# RA2A1 register map
Vendor: Renesas Electronics Corporation; Series: RA2; File version: 1.1
CPU: other r1p0, little endian, MPU, no FPU, VTOR, 2 interrupt priority bits
Registers are 8-bit, read-write, reset 0x0 unless marked. A register's access mark holds for its fields unless they carry their own. Offsets are from the block's base; [hi:lo] are bit positions; {n}, {i} and the like mark numbered series; 'fields as' and 'values as' point back to an identical list.

## PFS — Pmn Pin Function Control Register
Base 0x40040800
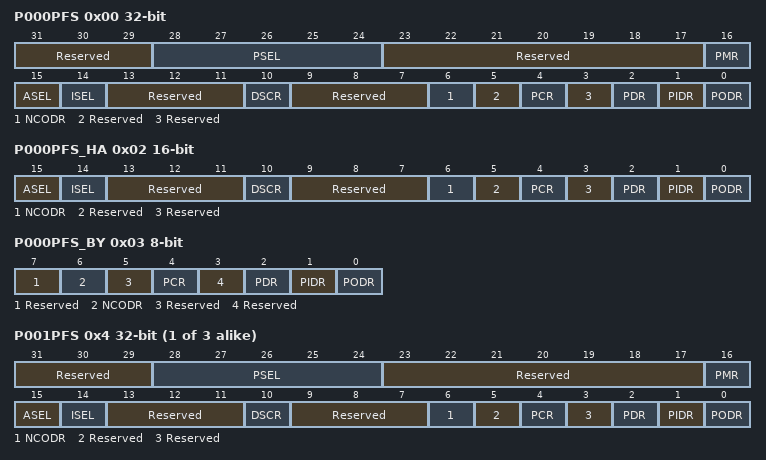
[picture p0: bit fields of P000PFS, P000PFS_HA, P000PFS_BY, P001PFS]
0x00 P000PFS 32-bit — P000 Pin Function Control Register
  [31:29] Reserved — These bits are read as 000. The write value should be 000.
  [28:24] PSEL — Port Function Select These bits select the peripheral function. For individual pin functions, see the MPC table
  [23:17] Reserved — These bits are read as 0000000. The write value should be 0000000.
  [16] PMR — Port Mode Control
    0=Uses the pin as a general I/O pin; 1=Uses the pin as an I/O port for peripheral functions
  [15] ASEL — Analog Input enable
    0=Used other than as analog pin; 1=Used as analog pin
  [14] ISEL — IRQ input enable
    0=Not used as IRQn input pin; 1=Used as IRQn input pin
  [13:11] Reserved — These bits are read as 000. The write value should be 000.
  [10] DSCR — Drive Strength Control Register
    0=Low drive; 1=High drive
  [9:7] Reserved — These bits are read as 000. The write value should be 000.
  [6] NCODR — N-Channel Open Drain Control
    0=CMOS output; 1=NMOS open-drain output
  [5] Reserved — This bit is read as 0. The write value should be 0.
  [4] PCR — Pull-up Control
    0=Disables an input pull-up; 1=Enables an input pull-up
  [3] Reserved — This bit is read as 0. The write value should be 0.
  [2] PDR — Port Direction
    0=Input (Functions as an input pin.); 1=Output (Functions as an output pin.)
  [1] PIDR ro — Port Input Data
    0=Low input; 1=High input
  [0] PODR — Port Output Data
    0=Low output; 1=High output
0x02 P000PFS_HA 16-bit — P000 Pin Function Control Register
  [15] ASEL — Analog Input enable
    0=Used other than as analog pin; 1=Used as analog pin
  [14] ISEL — IRQ input enable
    0=Not used as IRQn input pin; 1=Used as IRQn input pin
  [13:11] Reserved — These bits are read as 000. The write value should be 000.
  [10] DSCR — Drive Strength Control Register
    0=Low drive; 1=High drive
  [9:7] Reserved — These bits are read as 000. The write value should be 000.
  [6] NCODR — N-Channel Open Drain Control
    0=CMOS output; 1=NMOS open-drain output
  [5] Reserved — This bit is read as 0. The write value should be 0.
  [4] PCR — Pull-up Control
    0=Disables an input pull-up; 1=Enables an input pull-up
  [3] Reserved — This bit is read as 0. The write value should be 0.
  [2] PDR — Port Direction
    values as P000PFS.PDR
  [1] PIDR ro — Port Input Data
    0=Low input; 1=High input
  [0] PODR — Port Output Data
    0=Low output; 1=High output
0x03 P000PFS_BY — P000 Pin Function Control Register
  [7] Reserved — This bit is read as 0. The write value should be 0.
  [6] NCODR — N-Channel Open Drain Control
    0=CMOS output; 1=NMOS open-drain output
  [5] Reserved — This bit is read as 0. The write value should be 0.
  [4] PCR — Pull-up Control
    0=Disables an input pull-up; 1=Enables an input pull-up
  [3] Reserved — This bit is read as 0. The write value should be 0.
  [2] PDR — Port Direction
    values as P000PFS.PDR
  [1] PIDR ro — Port Input Data
    0=Low input; 1=High input
  [0] PODR — Port Output Data
    0=Low output; 1=High output
{0x0+4i} P00{i}PFS (i=1..3) 32-bit — P00{i} Pin Function Control Register
  fields as P000PFS
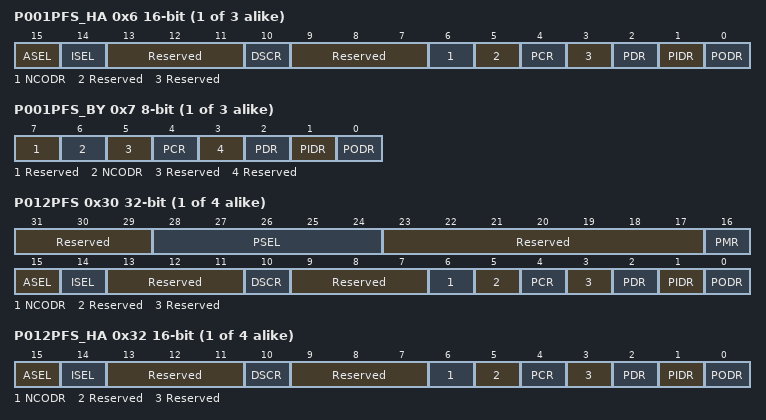
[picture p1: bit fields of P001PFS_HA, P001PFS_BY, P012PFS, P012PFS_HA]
{0x2+4i} P00{i}PFS_HA (i=1..3) 16-bit — P00{i} Pin Function Control Register
  fields as P000PFS_HA
{0x3+4i} P00{i}PFS_BY (i=1..3) — P00{i} Pin Function Control Register
  fields as P000PFS_BY
{0x0+4i} P0{i}PFS (i=12..15) 32-bit — P0{i} Pin Function Control Register
  fields as P000PFS
{0x2+4i} P0{i}PFS_HA (i=12..15) 16-bit — P0{i} Pin Function Control Register
  fields as P000PFS_HA
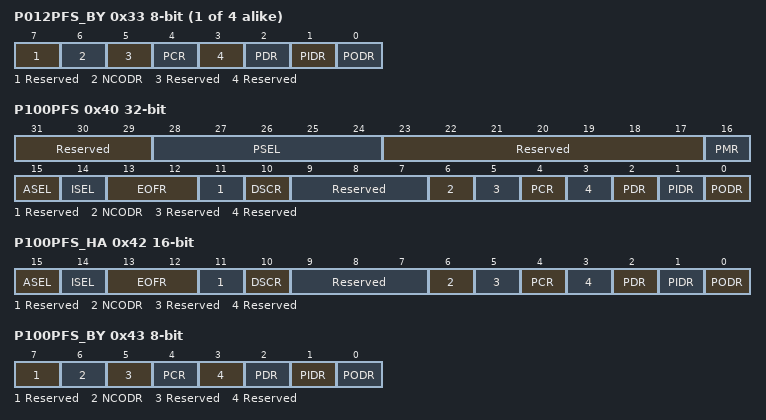
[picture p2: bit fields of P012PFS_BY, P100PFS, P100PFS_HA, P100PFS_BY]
{0x3+4i} P0{i}PFS_BY (i=12..15) — P0{i} Pin Function Control Register
  fields as P000PFS_BY
0x40 P100PFS 32-bit — P100 Pin Function Control Register
  [31:29] Reserved — These bits are read as 000. The write value should be 000.
  [28:24] PSEL — Port Function Select These bits select the peripheral function. For individual pin functions, see the MPC table
  [23:17] Reserved — These bits are read as 0000000. The write value should be 0000000.
  [16] PMR — Port Mode Control
    values as P000PFS.PMR
  [15] ASEL — Analog Input enable
    0=Used other than as analog pin; 1=Used as analog pin
  [14] ISEL — IRQ input enable
    0=Not used as IRQn input pin; 1=Used as IRQn input pin
  [13:12] EOFR — Event on Falling/Event on Rising
    0=Don't care; 1=Detect rising edge; 2=Detect falling edge; 3=Detect both edge
  [11] Reserved — This bit is read as 0. The write value should be 0.
  [10] DSCR — Drive Strength Control Register
    0=Low drive; 1=High drive
  [9:7] Reserved — These bits are read as 000. The write value should be 000.
  [6] NCODR — N-Channel Open Drain Control
    0=CMOS output; 1=NMOS open-drain output
  [5] Reserved — This bit is read as 0. The write value should be 0.
  [4] PCR — Pull-up Control
    0=Disables an input pull-up; 1=Enables an input pull-up
  [3] Reserved — This bit is read as 0. The write value should be 0.
  [2] PDR — Port Direction
    values as P000PFS.PDR
  [1] PIDR ro — Port Input Data
    0=Low input; 1=High input
  [0] PODR — Port Output Data
    0=Low output; 1=High output
0x42 P100PFS_HA 16-bit — P100 Pin Function Control Register
  [15] ASEL — Analog Input enable
    0=Used other than as analog pin; 1=Used as analog pin
  [14] ISEL — IRQ input enable
    0=Not used as IRQn input pin; 1=Used as IRQn input pin
  [13:12] EOFR — Event on Falling/Event on Rising
    values as P100PFS.EOFR
  [11] Reserved — This bit is read as 0. The write value should be 0.
  [10] DSCR — Drive Strength Control Register
    0=Low drive; 1=High drive
  [9:7] Reserved — These bits are read as 000. The write value should be 000.
  [6] NCODR — N-Channel Open Drain Control
    0=CMOS output; 1=NMOS open-drain output
  [5] Reserved — This bit is read as 0. The write value should be 0.
  [4] PCR — Pull-up Control
    0=Disables an input pull-up; 1=Enables an input pull-up
  [3] Reserved — This bit is read as 0. The write value should be 0.
  [2] PDR — Port Direction
    values as P000PFS.PDR
  [1] PIDR ro — Port Input Data
    0=Low input; 1=High input
  [0] PODR — Port Output Data
    0=Low output; 1=High output
0x43 P100PFS_BY — P100 Pin Function Control Register
  fields as P000PFS_BY
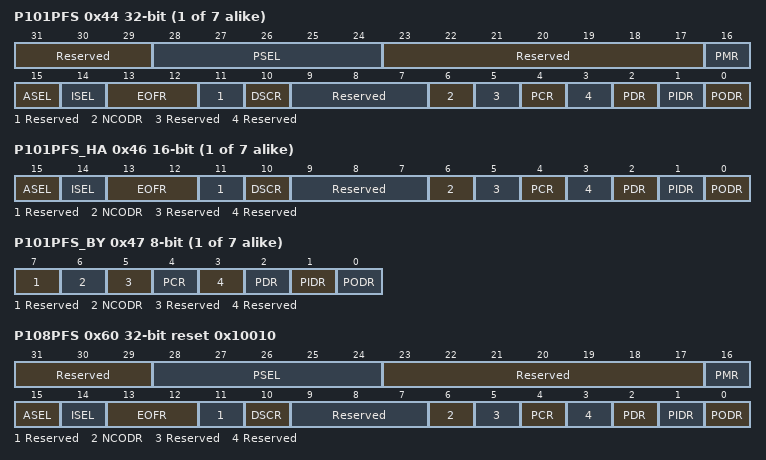
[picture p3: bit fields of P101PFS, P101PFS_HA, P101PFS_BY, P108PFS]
{0x40+4i} P10{i}PFS (i=1..7) 32-bit — P10{i} Pin Function Control Register
  fields as P100PFS
{0x42+4i} P10{i}PFS_HA (i=1..7) 16-bit — P10{i} Pin Function Control Register
  fields as P100PFS_HA
{0x43+4i} P10{i}PFS_BY (i=1..7) — P10{i} Pin Function Control Register
  fields as P000PFS_BY
0x60 P108PFS 32-bit reset 0x10010 — P108 Pin Function Control Register
  fields as P100PFS
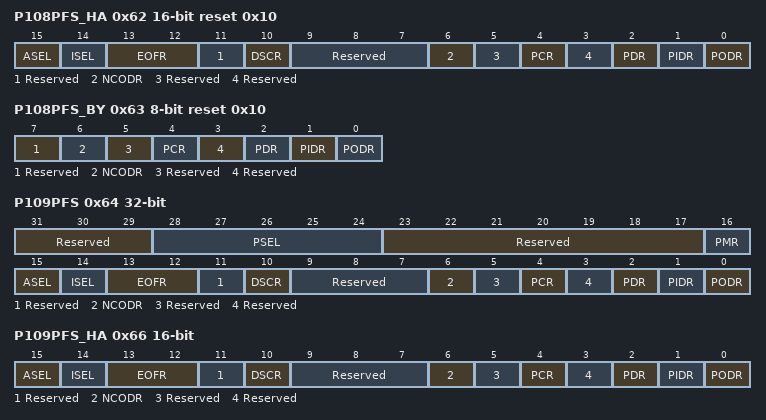
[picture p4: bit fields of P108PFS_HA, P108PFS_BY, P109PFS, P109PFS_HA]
0x62 P108PFS_HA 16-bit reset 0x10 — P108 Pin Function Control Register
  fields as P100PFS_HA
0x63 P108PFS_BY reset 0x10 — P108 Pin Function Control Register
  fields as P000PFS_BY
0x64 P109PFS 32-bit — P109 Pin Function Control Register
  fields as P100PFS
0x66 P109PFS_HA 16-bit — P109 Pin Function Control Register
  fields as P100PFS_HA
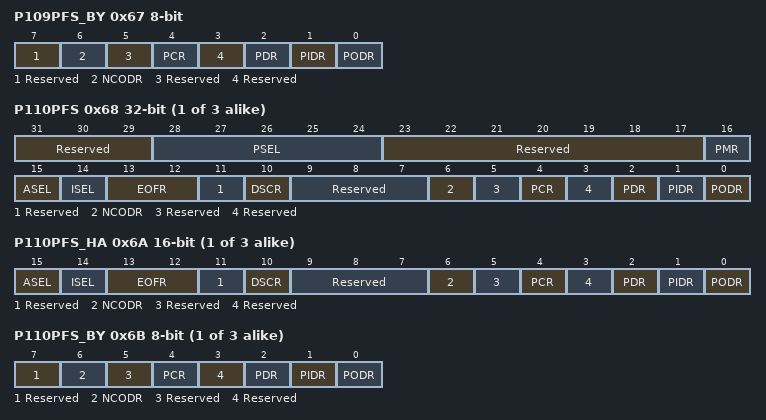
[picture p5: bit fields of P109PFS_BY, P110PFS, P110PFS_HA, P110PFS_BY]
0x67 P109PFS_BY — P109 Pin Function Control Register
  fields as P000PFS_BY
{0x40+4i} P1{i}PFS (i=10..12) 32-bit — P1{i} Pin Function Control Register
  fields as P100PFS
{0x42+4i} P1{i}PFS_HA (i=10..12) 16-bit — P1{i} Pin Function Control Register
  fields as P100PFS_HA
{0x43+4i} P1{i}PFS_BY (i=10..12) — P1{i} Pin Function Control Register
  fields as P000PFS_BY
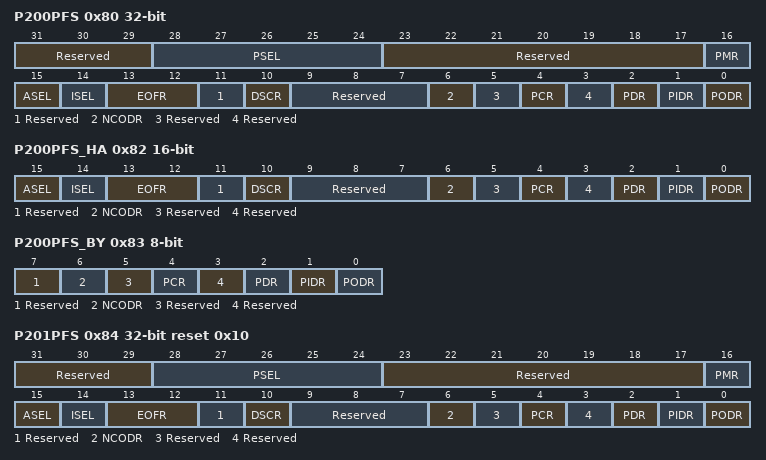
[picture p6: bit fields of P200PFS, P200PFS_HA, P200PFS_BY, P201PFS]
0x80 P200PFS 32-bit — P200 Pin Function Control Register
  fields as P100PFS
0x82 P200PFS_HA 16-bit — P200 Pin Function Control Register
  fields as P100PFS_HA
0x83 P200PFS_BY — P200 Pin Function Control Register
  fields as P000PFS_BY
0x84 P201PFS 32-bit reset 0x10 — P201 Pin Function Control Register
  fields as P100PFS
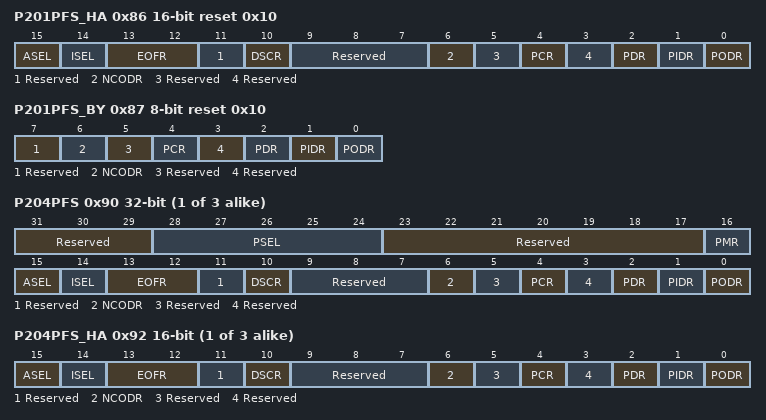
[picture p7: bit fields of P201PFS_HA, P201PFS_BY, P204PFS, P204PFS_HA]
0x86 P201PFS_HA 16-bit reset 0x10 — P201 Pin Function Control Register
  fields as P100PFS_HA
0x87 P201PFS_BY reset 0x10 — P201 Pin Function Control Register
  fields as P000PFS_BY
{0x80+4i} P20{i}PFS (i=4..6) 32-bit — P20{i} Pin Function Control Register
  fields as P100PFS
{0x82+4i} P20{i}PFS_HA (i=4..6) 16-bit — P20{i} Pin Function Control Register
  fields as P100PFS_HA
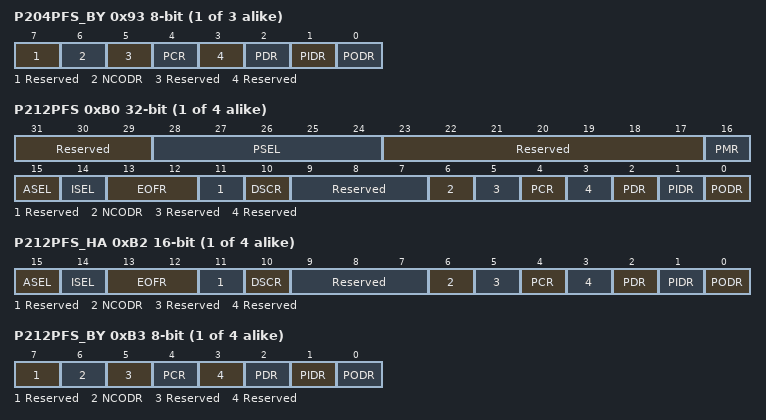
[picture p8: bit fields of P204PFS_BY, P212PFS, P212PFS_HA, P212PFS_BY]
{0x83+4i} P20{i}PFS_BY (i=4..6) — P20{i} Pin Function Control Register
  fields as P000PFS_BY
{0x80+4i} P2{i}PFS (i=12..15) 32-bit — P2{i} Pin Function Control Register
  fields as P100PFS
{0x82+4i} P2{i}PFS_HA (i=12..15) 16-bit — P2{i} Pin Function Control Register
  fields as P100PFS_HA
{0x83+4i} P2{i}PFS_BY (i=12..15) — P2{i} Pin Function Control Register
  fields as P000PFS_BY
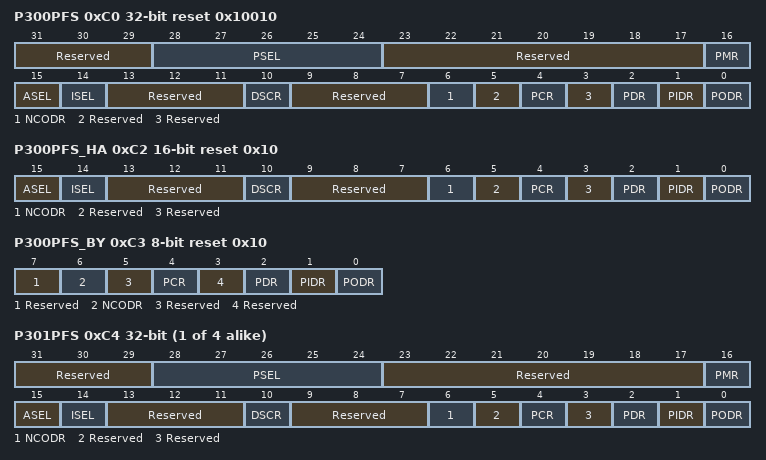
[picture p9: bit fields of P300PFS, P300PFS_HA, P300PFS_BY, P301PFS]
0xC0 P300PFS 32-bit reset 0x10010 — P300 Pin Function Control Register
  fields as P000PFS
0xC2 P300PFS_HA 16-bit reset 0x10 — P300 Pin Function Control Register
  fields as P000PFS_HA
0xC3 P300PFS_BY reset 0x10 — P300 Pin Function Control Register
  fields as P000PFS_BY
{0xC0+4i} P30{i}PFS (i=1..4) 32-bit — P30{i} Pin Function Control Register
  fields as P000PFS
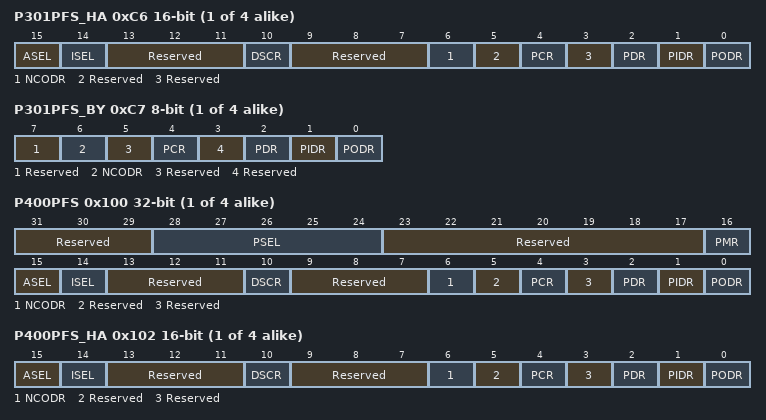
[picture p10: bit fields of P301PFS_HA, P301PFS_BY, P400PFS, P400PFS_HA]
{0xC2+4i} P30{i}PFS_HA (i=1..4) 16-bit — P30{i} Pin Function Control Register
  fields as P000PFS_HA
{0xC3+4i} P30{i}PFS_BY (i=1..4) — P30{i} Pin Function Control Register
  fields as P000PFS_BY
{0x100+4i} P40{i}PFS (i=0..3) 32-bit — P40{i} Pin Function Control Register
  fields as P000PFS
{0x102+4i} P40{i}PFS_HA (i=0..3) 16-bit — P40{i} Pin Function Control Register
  fields as P000PFS_HA
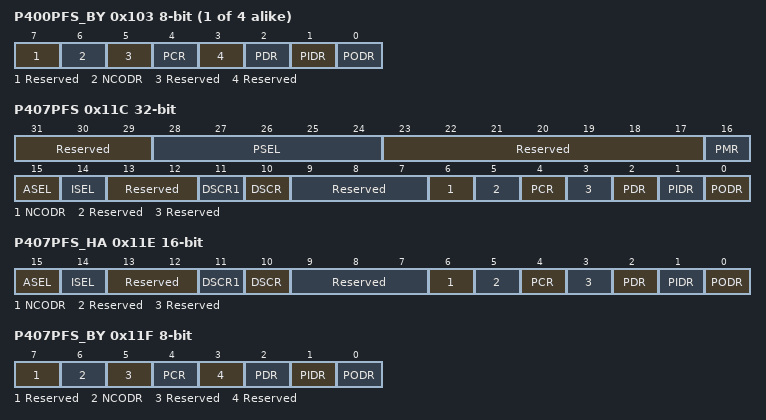
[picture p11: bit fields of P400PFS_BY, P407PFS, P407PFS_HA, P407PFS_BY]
{0x103+4i} P40{i}PFS_BY (i=0..3) — P40{i} Pin Function Control Register
  fields as P000PFS_BY
0x11C P407PFS 32-bit — P407 Pin Function Control Register
  [31:29] Reserved — These bits are read as 000. The write value should be 000.
  [28:24] PSEL — Port Function Select These bits select the peripheral function. For individual pin functions, see the MPC table
  [23:17] Reserved — These bits are read as 0000000. The write value should be 0000000.
  [16] PMR — Port Mode Control
    values as P000PFS.PMR
  [15] ASEL — Analog Input enable
    0=Used other than as analog pin; 1=Used as analog pin
  [14] ISEL — IRQ input enable
    0=Not used as IRQn input pin; 1=Used as IRQn input pin
  [13:12] Reserved — These bits are read as 00. The write value should be 00.
  [11] DSCR1 — Drive Strength Control Register
    0=Low drive; 1=Middle drive; 2=Middle drive for IIC Fast-mode and SPI; 3=Setting prohibited
  [10] DSCR
  [9:7] Reserved — These bits are read as 000. The write value should be 000.
  [6] NCODR — N-Channel Open Drain Control
    0=CMOS output; 1=NMOS open-drain output
  [5] Reserved — This bit is read as 0. The write value should be 0.
  [4] PCR — Pull-up Control
    0=Disables an input pull-up; 1=Enables an input pull-up
  [3] Reserved — This bit is read as 0. The write value should be 0.
  [2] PDR — Port Direction
    values as P000PFS.PDR
  [1] PIDR ro — Port Input Data
    0=Low input; 1=High input
  [0] PODR — Port Output Data
    0=Low output; 1=High output
0x11E P407PFS_HA 16-bit — P407 Pin Function Control Register
  [15] ASEL — Analog Input enable
    0=Used other than as analog pin; 1=Used as analog pin
  [14] ISEL — IRQ input enable
    0=Not used as IRQn input pin; 1=Used as IRQn input pin
  [13:12] Reserved — These bits are read as 00. The write value should be 00.
  [11] DSCR1 — Drive Strength Control Register
    values as P407PFS.DSCR1
  [10] DSCR
  [9:7] Reserved — These bits are read as 000. The write value should be 000.
  [6] NCODR — N-Channel Open Drain Control
    0=CMOS output; 1=NMOS open-drain output
  [5] Reserved — This bit is read as 0. The write value should be 0.
  [4] PCR — Pull-up Control
    0=Disables an input pull-up; 1=Enables an input pull-up
  [3] Reserved — This bit is read as 0. The write value should be 0.
  [2] PDR — Port Direction
    values as P000PFS.PDR
  [1] PIDR ro — Port Input Data
    0=Low input; 1=High input
  [0] PODR — Port Output Data
    0=Low output; 1=High output
0x11F P407PFS_BY — P407 Pin Function Control Register
  fields as P000PFS_BY
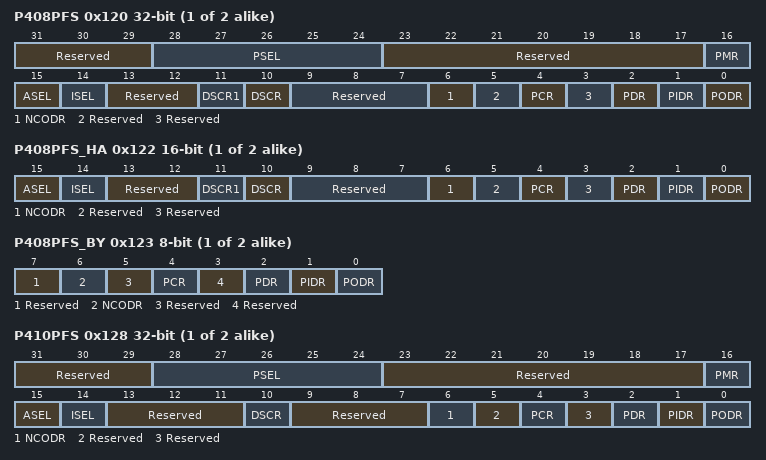
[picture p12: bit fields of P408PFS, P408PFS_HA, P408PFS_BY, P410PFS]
{0x100+4i} P40{i}PFS (i=8..9) 32-bit — P40{i} Pin Function Control Register
  fields as P407PFS
{0x102+4i} P40{i}PFS_HA (i=8..9) 16-bit — P40{i} Pin Function Control Register
  fields as P407PFS_HA
{0x103+4i} P40{i}PFS_BY (i=8..9) — P40{i} Pin Function Control Register
  fields as P000PFS_BY
{0x100+4i} P4{i}PFS (i=10..11) 32-bit — P4{i} Pin Function Control Register
  fields as P000PFS
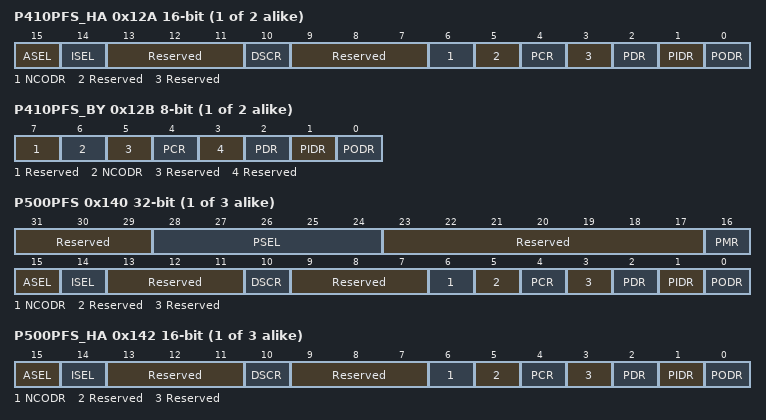
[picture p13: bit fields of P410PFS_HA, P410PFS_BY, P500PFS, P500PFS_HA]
{0x102+4i} P4{i}PFS_HA (i=10..11) 16-bit — P4{i} Pin Function Control Register
  fields as P000PFS_HA
{0x103+4i} P4{i}PFS_BY (i=10..11) — P4{i} Pin Function Control Register
  fields as P000PFS_BY
{0x140+4i} P50{i}PFS (i=0..2) 32-bit — P50{i} Pin Function Control Register
  fields as P000PFS
{0x142+4i} P50{i}PFS_HA (i=0..2) 16-bit — P50{i} Pin Function Control Register
  fields as P000PFS_HA
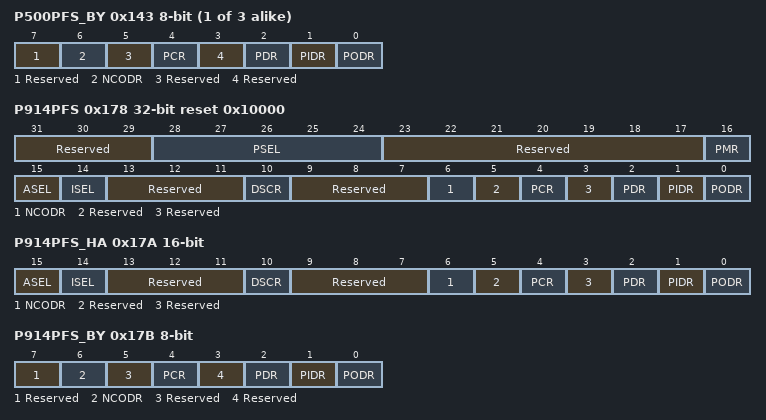
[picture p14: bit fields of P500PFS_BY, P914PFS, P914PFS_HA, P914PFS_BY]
{0x143+4i} P50{i}PFS_BY (i=0..2) — P50{i} Pin Function Control Register
  fields as P000PFS_BY
0x178 P914PFS 32-bit reset 0x10000 — P914 Pin Function Control Register
  fields as P000PFS
0x17A P914PFS_HA 16-bit — P914 Pin Function Control Register
  fields as P000PFS_HA
0x17B P914PFS_BY — P914 Pin Function Control Register
  fields as P000PFS_BY
0x17C P915PFS 32-bit reset 0x10000 — P915 Pin Function Control Register
  fields as P000PFS
0x17E P915PFS_HA 16-bit — P915 Pin Function Control Register
  fields as P000PFS_HA
0x17F P915PFS_BY — P915 Pin Function Control Register
  fields as P000PFS_BY
